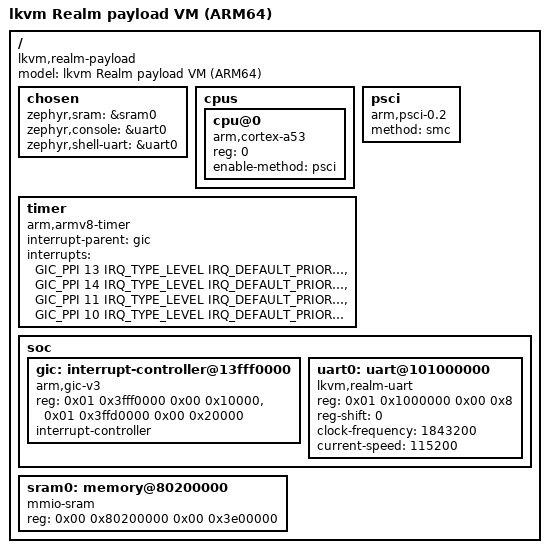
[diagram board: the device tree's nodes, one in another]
/dts-v1/;

#include <mem.h>
#include <arm64/armv8-a.dtsi>
#include <zephyr/dt-bindings/interrupt-controller/arm-gic.h>

/ {
	#address-cells = <2>;
	#size-cells = <2>;
	compatible = "lkvm,realm-payload";
	model = "lkvm Realm payload VM (ARM64)";

	chosen {
		zephyr,sram = &sram0;
		zephyr,console = &uart0;
		zephyr,shell-uart = &uart0;
	};

	cpus {
		#address-cells = <1>;
		#size-cells = <0>;
		cpu@0 {
			device_type = "cpu";
			compatible = "arm,cortex-a53";
			reg = <0>;
			enable-method = "psci";
		};
	};

	psci {
		compatible = "arm,psci-0.2";
		method = "smc";
	};

	timer {
		compatible = "arm,armv8-timer";
		interrupt-parent = <&gic>;
		interrupts = <GIC_PPI 13 IRQ_TYPE_LEVEL IRQ_DEFAULT_PRIORITY>,
			     <GIC_PPI 14 IRQ_TYPE_LEVEL IRQ_DEFAULT_PRIORITY>,
			     <GIC_PPI 11 IRQ_TYPE_LEVEL IRQ_DEFAULT_PRIORITY>,
			     <GIC_PPI 10 IRQ_TYPE_LEVEL IRQ_DEFAULT_PRIORITY>;
	};

	soc {
		#address-cells = <2>;
		#size-cells = <2>;
		ranges;

		gic: interrupt-controller@13fff0000 {
			compatible = "arm,gic-v3", "arm,gic";
			reg = <0x01 0x3fff0000 0x00 0x10000>,
			      <0x01 0x3ffd0000 0x00 0x20000>;
			interrupt-controller;
			#interrupt-cells = <4>;
			#address-cells = <2>;
			#size-cells = <2>;
			status = "okay";
		};

		uart0: uart@101000000 {
			compatible = "lkvm,realm-uart";
			reg = <0x01 0x1000000 0x00 0x8>;
			reg-shift = <0>;
			clock-frequency = <1843200>;
			current-speed = <115200>;
			status = "okay";
		};
	};

	/*
	 * The standalone Realm shim occupies the first 2 MiB of RAM at
	 * 0x80000000. The Zephyr payload is linked and loaded at 0x80200000.
	 */
	sram0: memory@80200000 {
		compatible = "mmio-sram";
		reg = <0x00 0x80200000 0x00 0x3e00000>;
	};
};
